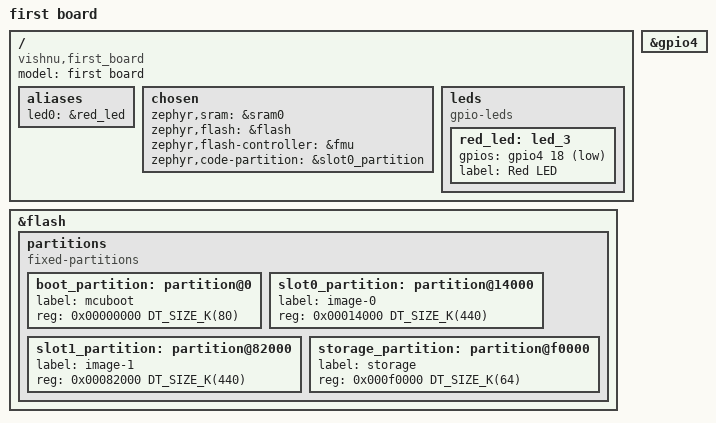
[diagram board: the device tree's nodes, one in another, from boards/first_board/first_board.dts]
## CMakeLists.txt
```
cmake_minimum_required(VERSION 3.20.0)

list(APPEND BOARD_ROOT ${CMAKE_CURRENT_SOURCE_DIR})
find_package(Zephyr REQUIRED)

project(l5-task2)

target_sources(app PRIVATE src/main.cpp)
```

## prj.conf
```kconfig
CONFIG_LED_BLINK_DELAY=1000
CONFIG_GPIO=y
```

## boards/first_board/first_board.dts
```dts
/dts-v1/;

#include <nxp/mcx/mcxn/nxp_mcxn23x.dtsi>

/ {
	model = "first board";
	compatible = "vishnu,first_board";

	aliases {
		led0 = &red_led;
	};

	chosen {
		zephyr,sram = &sram0;
		zephyr,flash = &flash;
		zephyr,flash-controller = &fmu;
		zephyr,code-partition = &slot0_partition;
	};

	leds {
		compatible = "gpio-leds";

		red_led: led_3 {
			gpios = <&gpio4 18 GPIO_ACTIVE_LOW>;
			label = "Red LED";
		};
	};
};

&gpio4 {
	status = "okay";
};

&flash {
	partitions {
		compatible = "fixed-partitions";
		#address-cells = <1>;
		#size-cells = <1>;

		boot_partition: partition@0 {
			label = "mcuboot";
			reg = <0x00000000 DT_SIZE_K(80)>;
		};

		slot0_partition: partition@14000 {
			label = "image-0";
			reg = <0x00014000 DT_SIZE_K(440)>;
		};

		slot1_partition: partition@82000 {
			label = "image-1";
			reg = <0x00082000 DT_SIZE_K(440)>;
		};

		storage_partition: partition@f0000 {
			label = "storage";
			reg = <0x000f0000 DT_SIZE_K(64)>;
		};
	};
};
```

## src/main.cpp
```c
#include <zephyr/kernel.h>
#include <zephyr/drivers/gpio.h>
#include <zephyr/init.h>
#include <zephyr/sys/printk.h>

#define RED_LED DT_ALIAS(red_led)
#define BLINK_DELAY CONFIG_LED_BLINK_DELAY

static const struct gpio_dt_spec red_led = GPIO_DT_SPEC_GET(RED_LED, gpios);

static int board_initialized(void)
{
    printk("Board Initialized\n");
    return 0;
}

SYS_INIT(board_initialized, APPLICATION, 0);

int main()
{
    gpio_pin_configure_dt(&red_led, GPIO_OUTPUT_ACTIVE);

    /* Infinite blink loop */
    while (1) {
        
        k_msleep(BLINK_DELAY);

        gpio_pin_toggle_dt(&red_led);

    }


    return 0;
}
```
